# S32K312_M7 register map
Vendor: NXP Semiconductors; File version: 1.3
CPU: CM7 r0p1, little endian, MPU, FPU, VTOR, 4 interrupt priority bits
Registers are 32-bit, read-write, reset 0x0 unless marked. A register's access mark holds for its fields unless they carry their own. Offsets are from the block's base; [hi:lo] are bit positions; {n}, {i} and the like mark numbered series.

## EDMA — DMA MP
Base 0x4020C000
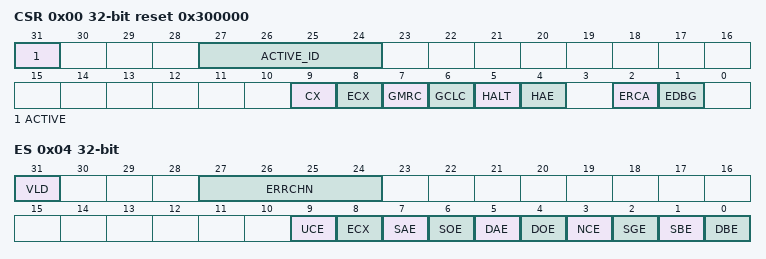
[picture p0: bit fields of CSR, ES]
0x00 CSR reset 0x300000 — Management Page Control
  [31] ACTIVE ro — DMA Active Status
    0=eDMA is idle; 1=eDMA is executing a channel
  [27:24] ACTIVE_ID ro — Active Channel ID
  [9] CX — Cancel Transfer
    0=Normal operation; 1=Cancel the remaining data transfer
  [8] ECX — Cancel Transfer With Error
    0=Normal operation; 1=Cancel the remaining data transfer
  [7] GMRC — Global Master ID Replication Control
    0=Master ID replication disabled for all channels; 1=Master ID replication available and controlled by each channel's CHn_SBR[EMI] setting
  [6] GCLC — Global Channel Linking Control
    0=Channel linking disabled for all channels; 1=Channel linking available and controlled by each channel's link settings
  [5] HALT — Halt DMA Operations
    0=Normal operation; 1=Stall the start of any new channels
  [4] HAE — Halt After Error
    0=Normal operation; 1=Any error causes the HALT field to be set to 1
  [2] ERCA — Enable Round Robin Channel Arbitration
    0=Round-robin channel arbitration disabled; 1=Round-robin channel arbitration enabled
  [1] EDBG — Enable Debug
    0=Debug mode disabled; 1=Debug mode is enabled
0x04 ES ro — Management Page Error Status
  [31] VLD — Valid
    0=No ERR fields are set to 1; 1=At least one ERR field is set to 1, indicating a valid error exists that software has not cleared
  [27:24] ERRCHN — Error Channel Number or Canceled Channel Number
  [9] UCE — Uncorrectable TCD Error During Channel Execution
    0=No uncorrectable ECC error; 1=Last recorded error was an uncorrectable TCD RAM error
  [8] ECX — Transfer Canceled
    0=No canceled transfers; 1=Last recorded entry was a canceled transfer by the error cancel transfer input
  [7] SAE — Source Address Error
    0=No source address configuration error; 1=Last recorded error was a configuration error detected in the TCDn_SADDR field
  [6] SOE — Source Offset Error
    0=No source offset configuration error; 1=Last recorded error was a configuration error detected in the TCDn_SOFF field
  [5] DAE — Destination Address Error
    0=No destination address configuration error; 1=Last recorded error was a configuration error detected in the TCDn_DADDR field
  [4] DOE — Destination Offset Error
    0=No destination offset configuration error; 1=Last recorded error was a configuration error detected in the TCDn_DOFF field
  [3] NCE — NBYTES/CITER Configuration Error
    0=No NBYTES/CITER configuration error; 1=The last recorded error was NBYTES equal to zero or a CITER not equal to BITER error
  [2] SGE — Scatter/Gather Configuration Error
    0=No scatter/gather configuration error; 1=Last recorded error was a configuration error detected in the TCDn_DLAST_SGA field
  [1] SBE — Source Bus Error
    0=No source bus error; 1=Last recorded error was a bus error on a source read
  [0] DBE — Destination Bus Error
    0=No destination bus error; 1=Last recorded error was a bus error on a destination write
0x08 INT ro — Management Page Interrupt Request Status
  [11:0] INT — Interrupt Request Status
0x0C HRS ro — Management Page Hardware Request Status
  [31:0] HRS — Hardware Request Status
{0x100+4i} CH_GRPRI[{i}] (i=0..11) — Channel Arbitration Group
  [4:0] GRPRI — Arbitration Group For Channel n

## MDM_AP
Base 0x40250600
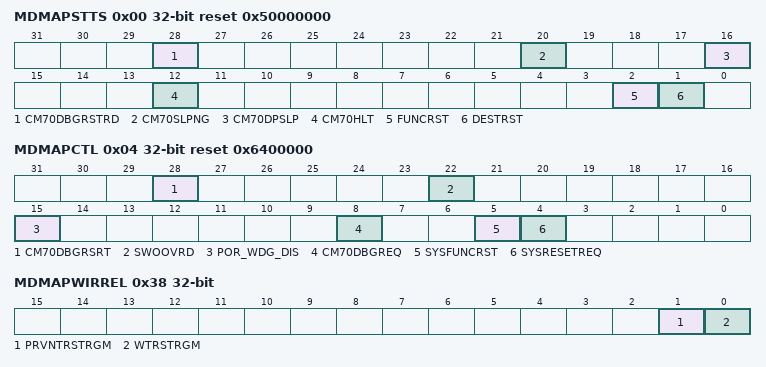
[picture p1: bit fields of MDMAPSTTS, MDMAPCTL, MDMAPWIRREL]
0x00 MDMAPSTTS ro reset 0x50000000 — Status
  [28] CM70DBGRSTRD — Cortex-M7_0 Debug Restarted
    0=In Debug mode; 1=In Normal mode
  [20] CM70SLPNG — Cortex-M7_0 Sleeping
    0=Not in Sleep mode; 1=In Sleep mode
  [16] CM70DPSLP — Cortex-M7_0 Deep Sleep
    0=Not in Deep Sleep mode; 1=In Deep Sleep mode
  [12] CM70HLT — Cortex-M7_0 Halted
    0=Core is not halted; 1=Core is halted
  [2] FUNCRST — Functional Reset
    0=Not in functional reset; 1=In functional reset
  [1] DESTRST — Destructive Reset
    0=Not in destructive reset; 1=In destructive reset
0x04 MDMAPCTL reset 0x6400000 — Control
  [28] CM70DBGRSRT — Cortex-M7_0 Debug Restart
    0=Normal operation; 1=Request asserted
  [22] SWOOVRD — SWO Override
    0=Not overridden, and SWO generates the trace response; 1=Is overridden
  [15] POR_WDG_DIS — Power Watchdog Status
    0=Power watchdog is disabled; 1=Power watchdog is enabled
  [8] CM70DBGREQ — Cortex-M7_0 Debug Request
    0=Debug request is not generated; 1=Debug request is generated
  [5] SYSFUNCRST — System Functional Reset
    0=Deasserted; 1=Asserted
  [4] SYSRESETREQ — System Destructive Reset
    0=Deasserted; 1=Asserted
0x30 MDMAPWIREN — WIR Enable
  [0] LWPWREN — Low Power Debug Enable
    0=Disabled; 1=Enabled
0x34 MDMAPWIRSTTS ro — WIR Status
  [31:0] MDM_DAP_WIR_STATUS — MDM_AP WIR Status
0x38 MDMAPWIRREL — WIR Release
  [1] PRVNTRSTRGM — Prevent Reset
    0=Normal operation; 1=MC_RGM prevented
  [0] WTRSTRGM — Wait In Reset B
    0=Normal operation; 1=Wait supported
0xFC ID ro reset 0x1C0030 — Identity
